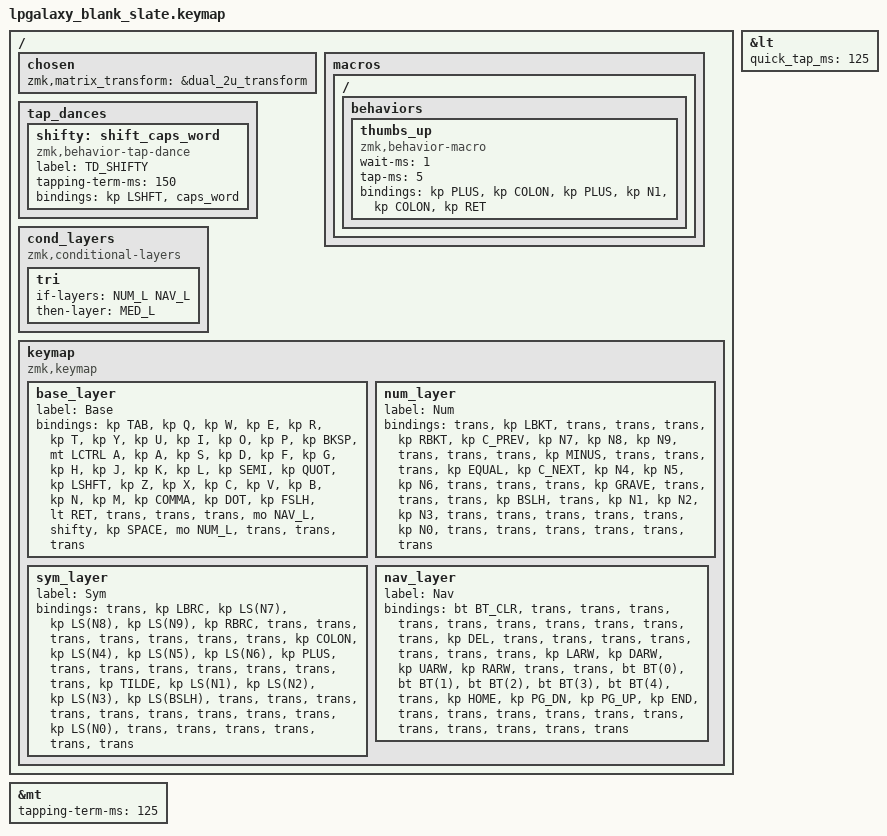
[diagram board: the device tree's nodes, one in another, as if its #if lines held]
/*
 * Copyright (c) 2022 Pete Johanson
 *
 * SPDX-License-Identifier: MIT
 */

#include <behaviors.dtsi>
#include <dt-bindings/zmk/keys.h>
#include <dt-bindings/zmk/bt.h>
#include <dt-bindings/zmk/outputs.h>

#define QWERTY_BASE 1
#define HYP(x) LS(LC(LA(LG(x))))

// #define TBLE_ORTHO   1
#define TBLE_MIT     1
// #define TBLE_DUAL_2U 1

#define NAV_L 1
#define NUM_L 2
#define MED_L 3
#define FUN_L 4

// Using layer taps on thumbs, having quick tap as well helps w/ repeating space/backspace
&lt { quick_tap_ms = <125>; };
&mt { tapping-term-ms = <125>; };

#define BT(n) BT_SEL n

/ {
    chosen {
       zmk,matrix_transform =
#ifdef TBLE_DUAL_2U
                       &dual_2u_transform;
#elif defined(TBLE_MIT)
                       &mit_transform;
#else
                       &ortho_transform;
#endif
    };

    macros {
      ZMK_MACRO(thumbs_up,
		wait-ms = <1>;
		tap-ms = <5>;
                bindings = <&kp PLUS &kp COLON &kp PLUS &kp N1 &kp COLON &kp RET>;
		)
    };
    
    tap_dances {
    	shifty: shift_caps_word {
		compatible = "zmk,behavior-tap-dance";
		label = "TD_SHIFTY";
		#binding-cells = <0>;
		tapping-term-ms = <150>;
		bindings = <&kp LSHFT>, <&caps_word>;
	};
    };

    cond_layers {
        compatible = "zmk,conditional-layers";
	tri {
	    if-layers = <NUM_L NAV_L>;
	    then-layer = <MED_L>;
        };
    };

    keymap {
        compatible = "zmk,keymap";

        base_layer {
            label = "Base";
            bindings = <
#ifdef QWERTY_BASE
 &kp TAB      &kp Q      &kp W      &kp E       &kp R          &kp T          &kp Y       &kp U          &kp I       &kp O      &kp P         &kp BKSP
 &mt LCTRL A  &kp A      &kp S      &kp D       &kp F          &kp G          &kp H       &kp J          &kp K       &kp L      &kp SEMI      &kp QUOT
 &kp LSHFT    &kp Z      &kp X      &kp C       &kp V          &kp B          &kp N       &kp M          &kp COMMA   &kp DOT    &kp FSLH      &lt RET
#else
  &kp Q      &kp W      &kp F       &kp P          &kp B   &none &none  &kp J            &kp L          &kp U       &kp Y      &kp QUOT
  &kp A      &kp R      &kp S       &kp T          &kp G   &none &none  &kp M            &kp N          &kp E       &kp I      &kp O
  &kp Z      &kp X      &kp C       &kp D          &kp V   &none &none  &kp K            &kp H          &kp COMMA   &kp DOT    &kp SEMI
#endif
#ifdef TBLE_DUAL_2U
&trans         &trans &trans    &mo NAV_L      &shifty      &kp SPACE        &mo NUM_L     &trans &trans &trans
#elif defined(TBLE_MIT)
 &kp HYP(4) &LCTRL  &kp LALT  &kp LGUI    &lt NAV_L KP_MINUS    &kp SPACE    &lt NUM_L  KP_PLUS       &kp LEFT  &kp DOWN  &kp UP  &kp RIGHT
#else
 &trans &trans         &kp LCTRL  &kp LALT    &mo NAV_L      &shifty      &kp SPACE        &mo NUM_L      &kp RALT    &kp RCTRL          &trans &trans
#endif
            >;
        };

        num_layer {
            label = "Num";
            bindings = <
&trans     &kp LBKT   &trans &trans &trans    &kp RBKT    &kp C_PREV    &kp N7     &kp N8      &kp N9       &trans     &trans
&trans     &kp MINUS  &trans &trans &trans    &kp EQUAL   &kp C_NEXT    &kp N4     &kp N5      &kp N6       &trans     &trans
&trans     &kp GRAVE  &trans &trans &trans    &kp BSLH    &trans        &kp N1     &kp N2      &kp N3       &trans     &trans
#ifdef TBLE_DUAL_2U
&trans  &trans       &trans     &kp N0              &trans                 &trans            &trans         &trans &trans &trans
#elif defined(TBLE_MIT)
&trans  &trans       &trans     &kp N0      &trans           &none            &trans        &kp DEL      &trans &trans &trans
#else
&trans  &trans       &trans     &kp N0      &trans    &none         &none     &kp ESC        &kp DEL      &trans &trans &trans
#endif
            >;
        };

        sym_layer {
            label = "Sym";
            bindings = <
&trans     &kp LBRC   &kp LS(N7) &kp LS(N8)  &kp LS(N9)   &kp RBRC     &trans     &trans    &trans       &trans       &trans     &trans
&trans     &kp COLON  &kp LS(N4) &kp LS(N5)  &kp LS(N6)   &kp PLUS     &trans     &trans    &trans       &trans       &trans     &trans
&trans     &kp TILDE  &kp LS(N1) &kp LS(N2)  &kp LS(N3)   &kp LS(BSLH) &trans     &trans    &trans       &trans       &trans     &trans
#ifdef TBLE_DUAL_2U
&trans &trans        &trans     &kp LS(N0)              &trans                    &trans       &trans         &trans &trans &trans
#elif defined(TBLE_MIT)
&trans &trans        &trans     &kp LS(N0)      &trans                &trans             &trans      &trans   &trans &trans &trans
#else
&trans &trans        &trans     &kp LS(N0)      &trans          &trans       &trans    &trans  &trans         &trans &trans &trans
#endif
            >;
        };
	
        nav_layer {
            label = "Nav";
            bindings = <
&bt BT_CLR &trans     &trans     &trans      &trans          &trans       &trans     &trans         &trans      &trans     &trans     &kp DEL
&trans     &trans     &trans     &trans      &trans          &trans       &trans     &kp LARW       &kp DARW    &kp UARW   &kp RARW   &trans
&trans     &bt BT(0)  &bt BT(1)  &bt BT(2)   &bt BT(3)       &bt BT(4)    &trans     &kp HOME       &kp PG_DN   &kp PG_UP  &kp END    &trans
#ifdef TBLE_DUAL_2U
&trans  &trans        &trans     &trans              &trans                    &trans       &trans         &trans &trans &trans
#elif defined(TBLE_MIT)
&trans  &trans        &trans     &trans      &trans                &trans             &trans      &trans   &trans &trans &trans
#else
&trans  &trans        &trans     &trans      &trans          &trans       &trans    &trans  &trans         &trans &trans &trans
#endif
            >;
        };


    };
};

